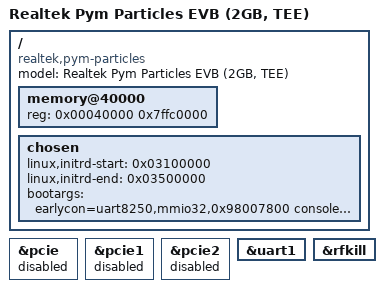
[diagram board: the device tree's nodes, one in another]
// SPDX-License-Identifier: (GPL-2.0-or-later OR BSD-2-Clause)
/*
 * Copyright (c) 2019-2020 Realtek Semiconductor Corp.
 */

/dts-v1/;

#include "rtd1319-pymparticles.dtsi"

/ {
	compatible = "realtek,pym-particles", "realtek,rtd1319";
	model = "Realtek Pym Particles EVB (2GB, TEE)";

	memory@40000 {
		device_type = "memory";
		reg = <0x00040000 0x7ffc0000>; /* 2 GiB */
	};

	chosen {
		linux,initrd-start = <0x03100000>;
		linux,initrd-end = <0x03500000>;
		bootargs = "earlycon=uart8250,mmio32,0x98007800 console=ttyS0,460800 init=/init loop.max_part=7 androidboot.storage=emmc androidboot.hardware=hank NO_RESERVE";
	};
};

&pcie {
	status = "disabled";
};

&pcie1 {
	status = "disabled";
};

&pcie2 {
	status = "disabled";
};

&uart1 {
	status = "okay";
};

&rfkill {
	status = "okay";
};
